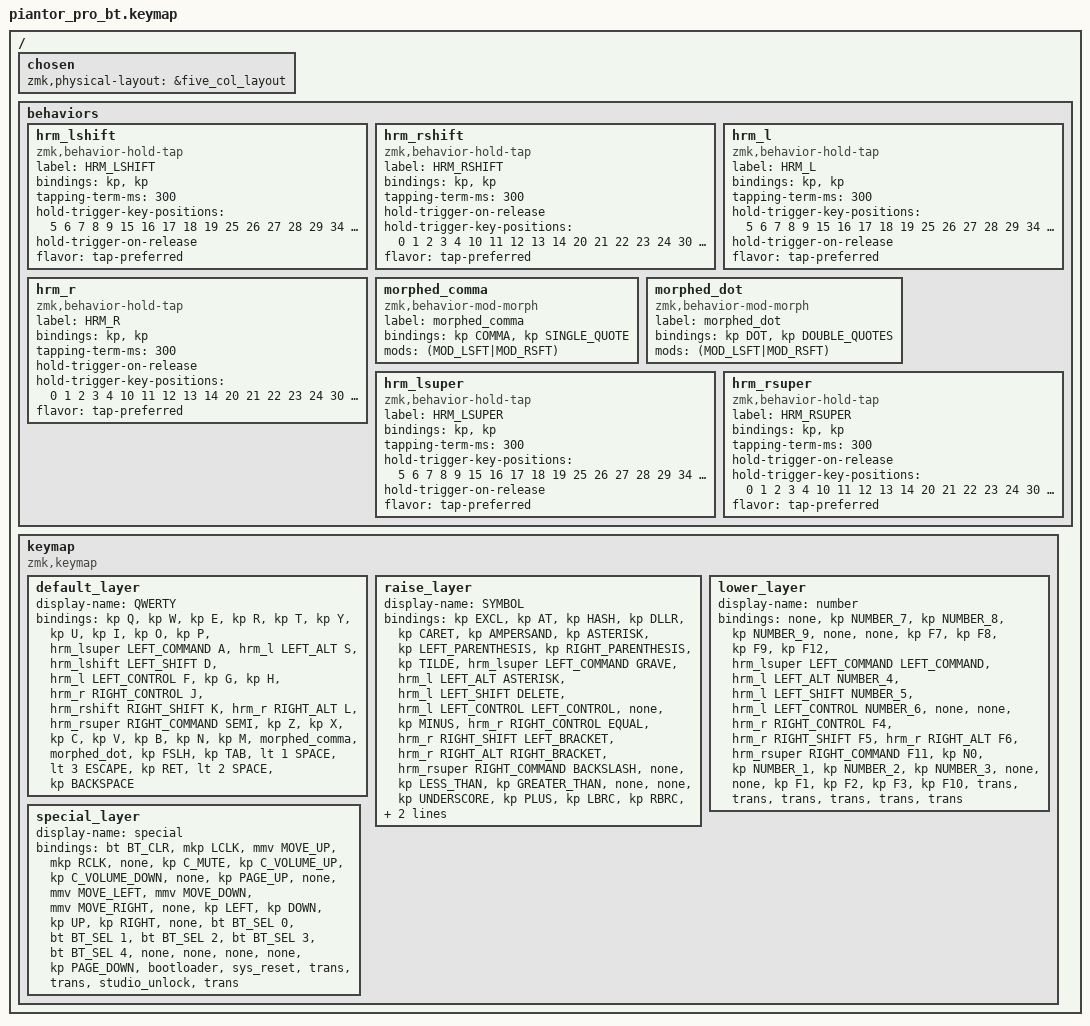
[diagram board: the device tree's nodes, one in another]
/*
 * Copyright (c) 2020 The ZMK Contributors
 *
 * SPDX-License-Identifier: MIT
 */

#include <behaviors.dtsi>
#include <dt-bindings/zmk/bt.h>
#include <dt-bindings/zmk/keys.h>
#include <dt-bindings/zmk/pointing.h>

/ {
    chosen { zmk,physical-layout = &five_col_layout; };
};

/ {
    behaviors {
        hrm_lshift: hrm_lshift {
            compatible = "zmk,behavior-hold-tap";
            label = "HRM_LSHIFT";
            bindings = <&kp>, <&kp>;

            #binding-cells = <2>;
            tapping-term-ms = <300>;
            hold-trigger-key-positions = <5 6 7 8 9 15 16 17 18 19 25 26 27 28 29 34 35 33>;
            hold-trigger-on-release;
            flavor = "tap-preferred";
        };

        hrm_rshift: hrm_rshift {
            compatible = "zmk,behavior-hold-tap";
            label = "HRM_RSHIFT";
            bindings = <&kp>, <&kp>;

            #binding-cells = <2>;
            tapping-term-ms = <300>;
            hold-trigger-on-release;
            hold-trigger-key-positions = <0 1 2 3 4 10 11 12 13 14 20 21 22 23 24 30 31 32>;
            flavor = "tap-preferred";
        };

        hrm_l: hrm_l {
            compatible = "zmk,behavior-hold-tap";
            label = "HRM_L";
            bindings = <&kp>, <&kp>;

            #binding-cells = <2>;
            tapping-term-ms = <300>;
            hold-trigger-key-positions = <5 6 7 8 9 15 16 17 18 19 25 26 27 28 29 34 35 33>;
            hold-trigger-on-release;
            flavor = "tap-preferred";
        };

        hrm_r: hrm_r {
            compatible = "zmk,behavior-hold-tap";
            label = "HRM_R";
            bindings = <&kp>, <&kp>;

            #binding-cells = <2>;
            tapping-term-ms = <300>;
            hold-trigger-on-release;
            hold-trigger-key-positions = <0 1 2 3 4 10 11 12 13 14 20 21 22 23 24 30 31 32>;
            flavor = "tap-preferred";
        };

        morphed_comma: morphed_comma {
            compatible = "zmk,behavior-mod-morph";
            label = "morphed_comma";
            bindings = <&kp COMMA>, <&kp SINGLE_QUOTE>;

            #binding-cells = <0>;
            mods = <(MOD_LSFT|MOD_RSFT)>;
        };

        morphed_dot: morphed_dot {
            compatible = "zmk,behavior-mod-morph";
            label = "morphed_dot";
            bindings = <&kp DOT>, <&kp DOUBLE_QUOTES>;

            #binding-cells = <0>;
            mods = <(MOD_LSFT|MOD_RSFT)>;
        };

        hrm_lsuper: hrm_lsuper {
            compatible = "zmk,behavior-hold-tap";
            label = "HRM_LSUPER";
            bindings = <&kp>, <&kp>;

            #binding-cells = <2>;
            tapping-term-ms = <300>;
            hold-trigger-key-positions = <5 6 7 8 9 15 16 17 18 19 25 26 27 28 29 34 35 33>;
            hold-trigger-on-release;
            flavor = "tap-preferred";
        };

        hrm_rsuper: hrm_rsuper {
            compatible = "zmk,behavior-hold-tap";
            label = "HRM_RSUPER";
            bindings = <&kp>, <&kp>;

            #binding-cells = <2>;
            tapping-term-ms = <300>;
            hold-trigger-on-release;
            hold-trigger-key-positions = <0 1 2 3 4 10 11 12 13 14 20 21 22 23 24 30 31 32>;
            flavor = "tap-preferred";
        };
    };

    keymap {
        compatible = "zmk,keymap";

        default_layer {
            display-name = "QWERTY";

            // --------------------------------------------------------------
            // |  Q  |  W  |  E  |  R  |  T  |  Y  |  U   |  I  |  O  |  P  |
            // |  A  |  S  |  D  |  F  |  G  |  H  |  J   |  K  |  L  |  ;  |
            // |  Z  |  X  |  C  |  V  |  B  |  N  |  M   |  ,  |  .  |  /  |
            //                    | GUI | LWR | SPC | ENT | RSE  | ALT |

            bindings = <
  &kp Q  &kp W  &kp E  &kp R  &kp T  &kp Y  &kp U  &kp I  &kp O  &kp P      &hrm_lsuper LEFT_COMMAND A  &hrm_l LEFT_ALT S  &hrm_lshift LEFT_SHIFT D  &hrm_l LEFT_CONTROL F  &kp G  &kp H  &hrm_r RIGHT_CONTROL J  &hrm_rshift RIGHT_SHIFT K  &hrm_r RIGHT_ALT L  &hrm_rsuper RIGHT_COMMAND SEMI      &kp Z  &kp X  &kp C  &kp V  &kp B  &kp N  &kp M  &morphed_comma  &morphed_dot  &kp FSLH    &kp TAB  &lt 1 SPACE  &lt 3 ESCAPE  &kp RET  &lt 2 SPACE  &kp BACKSPACE
            >;
        };

        raise_layer {
            display-name = "SYMBOL";

            // -------------------------------------------------------------
            // |  !  |  @  |  #  |  $  |  %  |  ^  |  &  |  *  |  (  |  )  |
            // |     |     |     |     |     |  -  |  =  |  [  |  ]  |  \  |
            // |     |     |     |     |     |  _  |  +  |  {  |  }  | "|" |
            //                    | GUI |     | SPC | ENT |     | ALT |

            bindings = <
  &kp EXCL  &kp AT  &kp HASH  &kp DLLR  &kp CARET  &kp AMPERSAND  &kp ASTERISK  &kp LEFT_PARENTHESIS  &kp RIGHT_PARENTHESIS  &kp TILDE      &hrm_lsuper LEFT_COMMAND GRAVE  &hrm_l LEFT_ALT ASTERISK  &hrm_l LEFT_SHIFT DELETE  &hrm_l LEFT_CONTROL LEFT_CONTROL  &none  &kp MINUS  &hrm_r RIGHT_CONTROL EQUAL  &hrm_r RIGHT_SHIFT LEFT_BRACKET  &hrm_r RIGHT_ALT RIGHT_BRACKET  &hrm_rsuper RIGHT_COMMAND BACKSLASH      &none  &kp LESS_THAN  &kp GREATER_THAN  &none  &none  &kp UNDERSCORE  &kp PLUS  &kp LBRC  &kp RBRC  &kp PIPE    &trans  &trans  &trans  &trans  &trans  &trans
            >;
        };

        lower_layer {
            display-name = "number";
            bindings = <
  &none  &kp NUMBER_7  &kp NUMBER_8  &kp NUMBER_9  &none  &none  &kp F7  &kp F8  &kp F9  &kp F12      &hrm_lsuper LEFT_COMMAND LEFT_COMMAND  &hrm_l LEFT_ALT NUMBER_4  &hrm_l LEFT_SHIFT NUMBER_5  &hrm_l LEFT_CONTROL NUMBER_6  &none  &none  &hrm_r RIGHT_CONTROL F4  &hrm_r RIGHT_SHIFT F5  &hrm_r RIGHT_ALT F6  &hrm_rsuper RIGHT_COMMAND F11      &kp N0  &kp NUMBER_1  &kp NUMBER_2  &kp NUMBER_3  &none  &none  &kp F1  &kp F2  &kp F3  &kp F10    &trans  &trans  &trans  &trans  &trans  &trans
            >;
        };

        special_layer {
            display-name = "special";

            // ---------------------------------------------------------------
            // |  1  |  2  |  3  |  4  |  5    |  6  |  7  |  8  |  9  |  0  |
            // | BT1 | BT2 | BT3 | BT4 | BT5   | LFT | DWN |  UP | RGT |     |
            // | BTCR| RGB | RST | BOOT| Unlock|     |     |     |     |     |
            //                    | GUI |     | SPC   | ENT |     | ALT |

            bindings = <
  &bt BT_CLR  &mkp LCLK  &mmv MOVE_UP  &mkp RCLK  &none  &kp C_MUTE  &kp C_VOLUME_UP  &kp C_VOLUME_DOWN  &none  &kp PAGE_UP      &none  &mmv MOVE_LEFT  &mmv MOVE_DOWN  &mmv MOVE_RIGHT  &none  &kp LEFT  &kp DOWN  &kp UP  &kp RIGHT  &none      &bt BT_SEL 0  &bt BT_SEL 1  &bt BT_SEL 2  &bt BT_SEL 3  &bt BT_SEL 4  &none  &none  &none  &none  &kp PAGE_DOWN    &bootloader  &sys_reset  &trans  &trans  &studio_unlock  &trans
            >;
        };
    };
};
